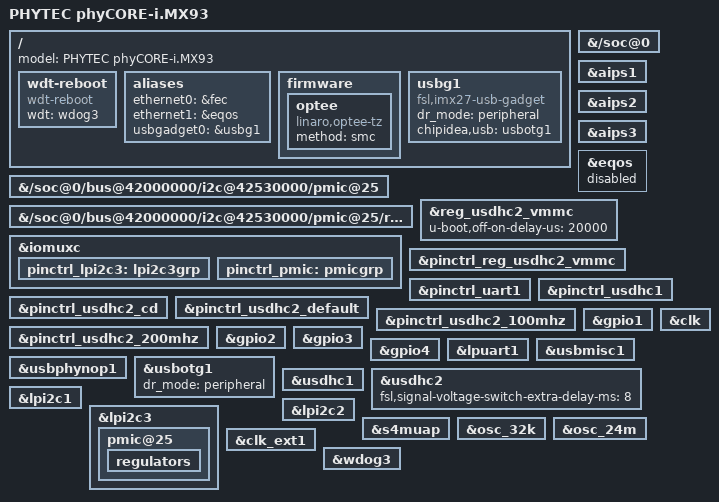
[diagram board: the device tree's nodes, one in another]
// SPDX-License-Identifier: (GPL-2.0+ OR MIT)
/*
 * Copyright (C) 2024 PHYTEC Messtechnik GmbH
 * Copyright (C) 2023 PHYTEC Messtechnik GmbH
 * Christoph Stoidner <c.stoidner@phytec.de>
 *
 */

#include "imx93-u-boot.dtsi"

/ {

	/*
	 * If the u-boot build uses the device tree of a phyCORE-i.MX93 carrier
	 * board (i.E. imx93-phyboard-segin.dts), then this u-boot.dtsi
	 * deactivates all carrier board-specific peripherals. This means that
	 * the resulting SPL and u-boot binary can boot the phyCORE-i.MX 93 module
	 * on each carrier board.
	 */
	model = "PHYTEC phyCORE-i.MX93";

	wdt-reboot {
		compatible = "wdt-reboot";
		wdt = <&wdog3>;
		bootph-pre-ram;
		bootph-some-ram;
	};

	aliases {
		ethernet0 = &fec;
		ethernet1 = &eqos;
		usbgadget0 = &usbg1;
	};

	firmware {
		optee {
			compatible = "linaro,optee-tz";
			method = "smc";
		};
	};

	usbg1: usbg1 {
		compatible = "fsl,imx27-usb-gadget";
		dr_mode = "peripheral";
		chipidea,usb = <&usbotg1>;
		status = "okay";
	};
};

&{/soc@0} {
	bootph-all;
	bootph-pre-ram;
};

&{/soc@0/bus@42000000/i2c@42530000/pmic@25} {
	bootph-pre-ram;
	bootph-some-ram;
};

&{/soc@0/bus@42000000/i2c@42530000/pmic@25/regulators} {
	bootph-pre-ram;
	bootph-some-ram;
};

&aips1 {
	bootph-pre-ram;
	bootph-all;
};

&aips2 {
	bootph-pre-ram;
	bootph-some-ram;
};

&aips3 {
	bootph-pre-ram;
	bootph-some-ram;
};

&iomuxc {
	bootph-pre-ram;
	bootph-some-ram;
};

&eqos {
	status = "disabled";
};

&reg_usdhc2_vmmc {
	u-boot,off-on-delay-us = <20000>;
	bootph-pre-ram;
	bootph-some-ram;
};

&pinctrl_reg_usdhc2_vmmc {
	bootph-pre-ram;
};

&pinctrl_uart1 {
	bootph-pre-ram;
	bootph-some-ram;
};

&pinctrl_usdhc1 {
	bootph-pre-ram;
	bootph-some-ram;
};

&pinctrl_usdhc2_cd {
	bootph-pre-ram;
	bootph-some-ram;
};

&pinctrl_usdhc2_default {
	bootph-pre-ram;
	bootph-some-ram;
};

&pinctrl_usdhc2_100mhz {
	bootph-pre-ram;
	bootph-some-ram;
};

&pinctrl_usdhc2_200mhz {
	bootph-pre-ram;
	bootph-some-ram;
};

&gpio1 {
	bootph-pre-ram;
	bootph-some-ram;
};

&gpio2 {
	bootph-pre-ram;
	bootph-some-ram;
};

&gpio3 {
	bootph-pre-ram;
	bootph-some-ram;
};

&gpio4 {
	bootph-pre-ram;
	bootph-some-ram;
};

&lpuart1 {
	bootph-pre-ram;
	bootph-some-ram;
};

&usbmisc1 {
	bootph-pre-ram;
	bootph-some-ram;
};

&usbphynop1 {
	bootph-pre-ram;
	bootph-some-ram;
};

&usbotg1 {
	dr_mode = "peripheral";
	bootph-pre-ram;
	bootph-some-ram;
};

&usdhc1 {
	bootph-pre-ram;
	bootph-some-ram;
};

&usdhc2 {
	bootph-pre-ram;
	bootph-some-ram;
	fsl,signal-voltage-switch-extra-delay-ms = <8>;
};

&lpi2c1 {
	bootph-pre-ram;
	bootph-some-ram;
};

&lpi2c2 {
	bootph-pre-ram;
	bootph-some-ram;
};

&lpi2c3 {
	bootph-pre-ram;
	bootph-some-ram;
};

&s4muap {
	bootph-pre-ram;
	bootph-some-ram;
	status = "okay";
};

&clk {
	bootph-all;
	bootph-pre-ram;
	/delete-property/ assigned-clocks;
	/delete-property/ assigned-clock-rates;
	/delete-property/ assigned-clock-parents;
};

&osc_32k {
	bootph-all;
	bootph-pre-ram;
};

&osc_24m {
	bootph-all;
	bootph-pre-ram;
};

&clk_ext1 {
	bootph-all;
	bootph-pre-ram;
};

&wdog3 {
	bootph-all;
	bootph-pre-ram;
};

&iomuxc {
	pinctrl_lpi2c3: lpi2c3grp {
		bootph-pre-ram;
	};

	pinctrl_pmic: pmicgrp {
		bootph-pre-ram;
	};
};

&lpi2c3 {
	bootph-pre-ram;
	bootph-some-ram;
	status = "okay";

	pmic@25 {
		bootph-pre-ram;
		bootph-some-ram;

		regulators {
			bootph-pre-ram;
			bootph-some-ram;
		};
	};
};
